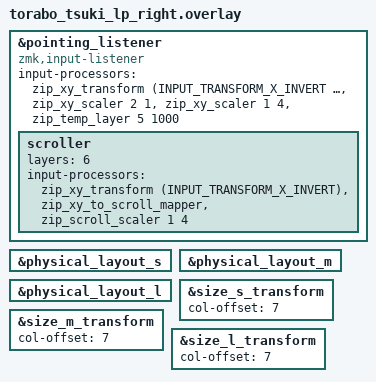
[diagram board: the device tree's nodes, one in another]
#include "torabo_tsuki_lp.dtsi"
#include <input/processors.dtsi>
#include <dt-bindings/zmk/input_transform.h>

/* ZMK v0.3で動作する標準命令のみで、完璧な倍率処理（誤発動カット）を構成します */
&pointing_listener {
    compatible = "zmk,input-listener";
    
    input-processors = 
        /* 1. トラックボールの生の動きを上下左右反転させます */
        <&zip_xy_transform (INPUT_TRANSFORM_X_INVERT | INPUT_TRANSFORM_Y_INVERT)>,
        /* 2. 【誤発動カットの魔法】動きを一旦「2倍」に拡大します */
        <&zip_xy_scaler 2 1>, 
        /* 3. すぐに「4分の1」に縮小します。これでかすった微小データが消滅し、かつ最終速度は「1/2速」になります */
        <&zip_xy_scaler 1 4>, 
        /* 4. ZMK v0.3で確実に動く、持続時間1秒（引数2つ）の安全なオートマウス設定 */
        <&zip_temp_layer 5 1000>; 

    /* レイヤー6のときだけスクロールにする設定（左右のみ反転・4分の1速度） */
    scroller {
        layers = <6>;
        input-processors = 
            <&zip_xy_transform (INPUT_TRANSFORM_X_INVERT)>, 
            <&zip_xy_to_scroll_mapper>, 
            <&zip_scroll_scaler 1 4>;
    };
};

/* ZMK v0.3環境で発生する「lacks #input-processor-cells」エラーを綺麗に補給・修正します */
&physical_layout_s { #input-processor-cells = <1>; };
&physical_layout_m { #input-processor-cells = <1>; };
&physical_layout_l { #input-processor-cells = <1>; };

/* エラーの原因になっている古い命令を、空っぽにして無効化（上書き）する */
/ {
    /delete-property/ automouse-layer;
};

&size_s_transform {
    col-offset = <7>;
};

&size_m_transform {
    col-offset = <7>;
};

&size_l_transform {
    col-offset = <7>;
};

